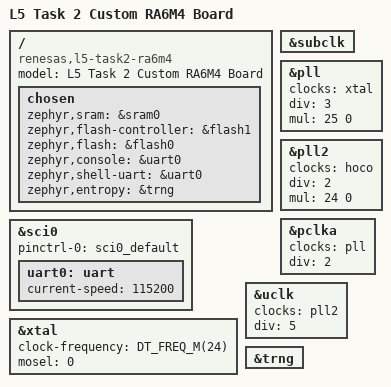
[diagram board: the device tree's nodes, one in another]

/*
 * SPDX-License-Identifier: Apache-2.0
 *
 * Custom RA6M4 board definition created from scratch.
 */

/dts-v1/;

#include <renesas/ra/ra6/r7fa6m4af3cfb.dtsi>
#include "l5_task2_ra6m4-pinctrl.dtsi"

/ {
    model = "L5 Task 2 Custom RA6M4 Board";
    compatible = "renesas,l5-task2-ra6m4", "renesas,ra";

    chosen {
        zephyr,sram = &sram0;
        zephyr,flash-controller = &flash1;
        zephyr,flash = &flash0;
        zephyr,console = &uart0;
        zephyr,shell-uart = &uart0;
        zephyr,entropy = &trng;
    };
};

&sci0 {
    pinctrl-0 = <&sci0_default>;
    pinctrl-names = "default";
    status = "okay";

    uart0: uart {
        current-speed = <115200>;
        status = "okay";
    };
};

&xtal {
    clock-frequency = <DT_FREQ_M(24)>;
    mosel = <0>;
    #clock-cells = <0>;
    status = "okay";
};

&subclk {
    status = "okay";
};

&pll {
    clocks = <&xtal>;
    div = <3>;
    mul = <25 0>;
    status = "okay";
};

&pll2 {
    clocks = <&hoco>;
    div = <2>;
    mul = <24 0>;
    status = "okay";
};

&pclka {
    clocks = <&pll>;
    div = <2>;
    status = "okay";
};

&uclk {
    clocks = <&pll2>;
    div = <5>;
    status = "okay";
};

&trng {
    status = "okay";
};
